VERSION ""

NS_ :

BS_:

BU_: PCM TCM BCM ECU

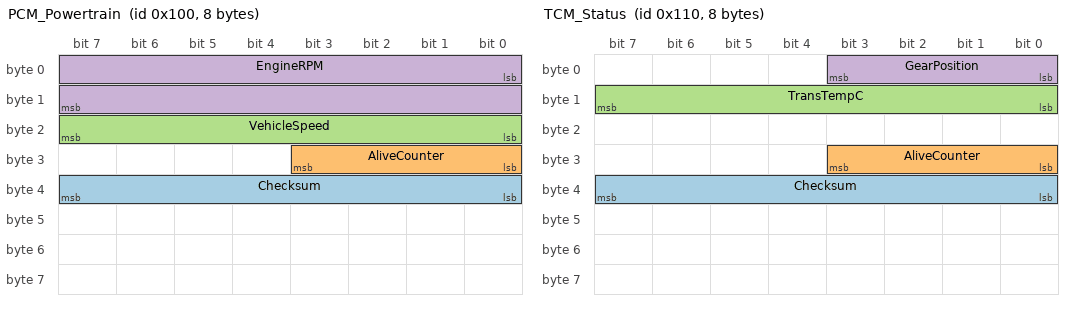
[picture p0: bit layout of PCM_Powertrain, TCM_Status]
BO_ 256 PCM_Powertrain: 8 PCM
 SG_ Checksum : 32|8@1+ (1,0) [0|0] ""  ECU
 SG_ AliveCounter : 24|4@1+ (1,0) [0|0] ""  ECU
 SG_ VehicleSpeed : 16|8@1+ (1,0) [0|0] "km/h"  ECU
 SG_ EngineRPM : 0|16@1+ (0.25,0) [0|0] "rpm"  ECU

BO_ 272 TCM_Status: 8 TCM
 SG_ Checksum : 32|8@1+ (1,0) [0|0] ""  ECU
 SG_ AliveCounter : 24|4@1+ (1,0) [0|0] ""  ECU
 SG_ TransTempC : 8|8@1+ (1,-40) [0|0] "degC"  ECU
 SG_ GearPosition : 0|4@1+ (1,0) [0|0] ""  ECU

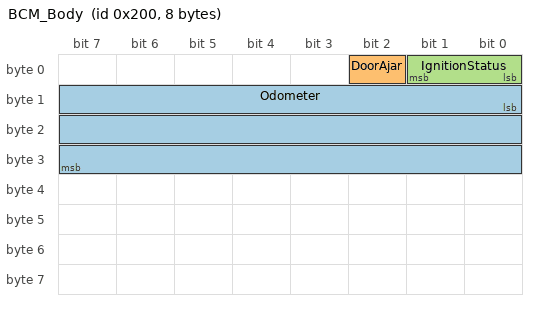
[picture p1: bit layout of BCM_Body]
BO_ 512 BCM_Body: 8 BCM
 SG_ Odometer : 8|24@1+ (1,0) [0|0] "km"  ECU
 SG_ DoorAjar : 2|1@1+ (1,0) [0|0] ""  ECU
 SG_ IgnitionStatus : 0|2@1+ (1,0) [0|0] ""  ECU
